AUTOSAR XML (schema 4-2-2)
package /STELLANTIS/EPT/SASWCs
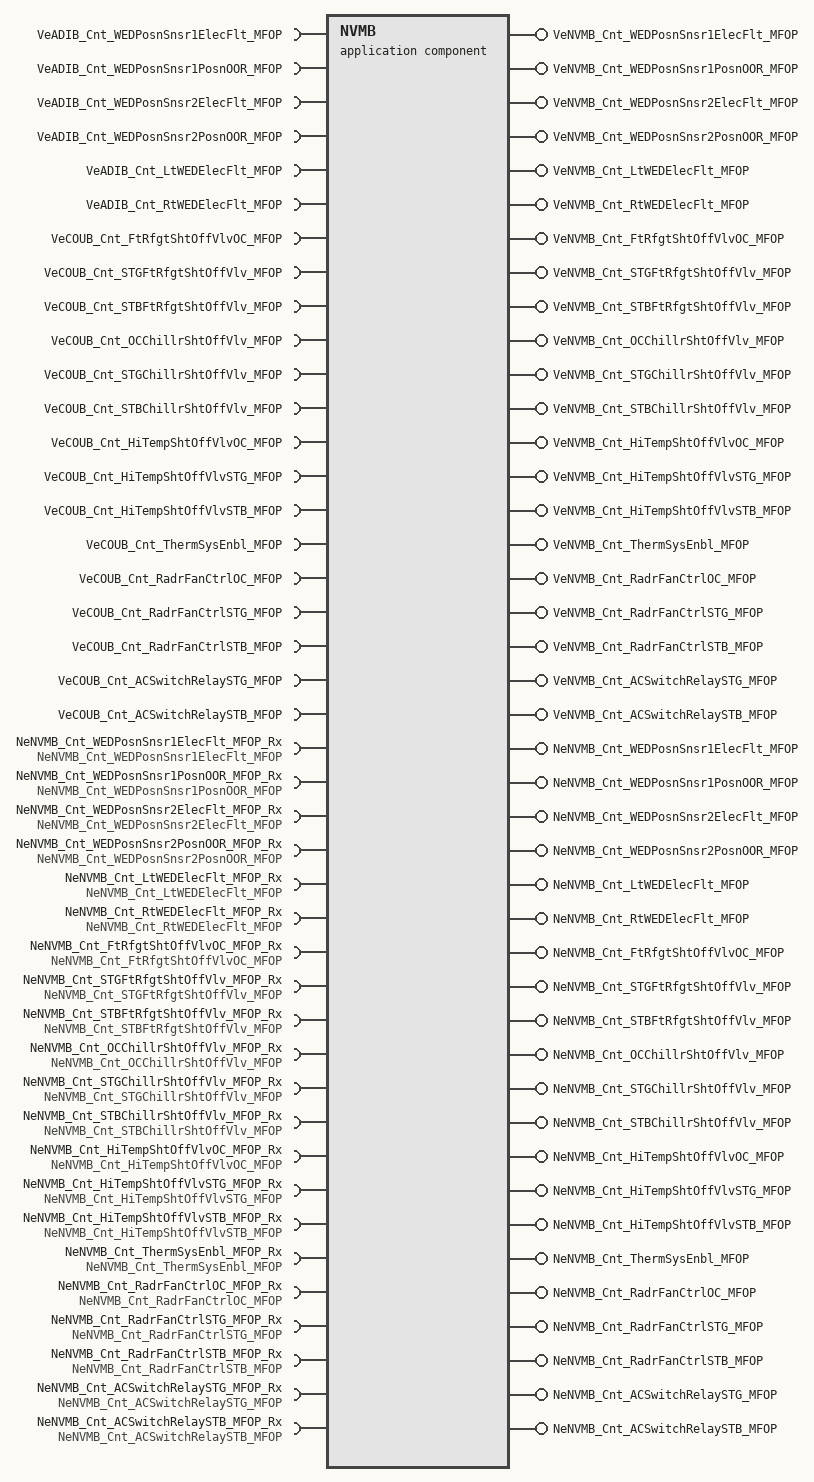
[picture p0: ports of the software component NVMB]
  application sw component type NVMB
    21 x require port, all with nonqueued-receiver-com-spec{data-element=Value, init-value=0}:
      VeADIB_Cnt_WEDPosnSnsr1ElecFlt_MFOP: variation-point={short-label=vpVeADIB_Cnt_WEDPosnSnsr1ElecFlt_MFOP, sw-syscond=1}, required-interface=VeADIB_Cnt_WEDPosnSnsr1ElecFlt_MFOP
      VeADIB_Cnt_WEDPosnSnsr1PosnOOR_MFOP: variation-point={short-label=vpVeADIB_Cnt_WEDPosnSnsr1PosnOOR_MFOP, sw-syscond=1}, required-interface=VeADIB_Cnt_WEDPosnSnsr1PosnOOR_MFOP
      VeADIB_Cnt_WEDPosnSnsr2ElecFlt_MFOP: variation-point={short-label=vpVeADIB_Cnt_WEDPosnSnsr2ElecFlt_MFOP, sw-syscond=1}, required-interface=VeADIB_Cnt_WEDPosnSnsr2ElecFlt_MFOP
      VeADIB_Cnt_WEDPosnSnsr2PosnOOR_MFOP: variation-point={short-label=vpVeADIB_Cnt_WEDPosnSnsr2PosnOOR_MFOP, sw-syscond=1}, required-interface=VeADIB_Cnt_WEDPosnSnsr2PosnOOR_MFOP
      VeADIB_Cnt_LtWEDElecFlt_MFOP: variation-point={short-label=vpVeADIB_Cnt_LtWEDElecFlt_MFOP, sw-syscond=1}, required-interface=VeADIB_Cnt_LtWEDElecFlt_MFOP
      VeADIB_Cnt_RtWEDElecFlt_MFOP: variation-point={short-label=vpVeADIB_Cnt_RtWEDElecFlt_MFOP, sw-syscond=1}, required-interface=VeADIB_Cnt_RtWEDElecFlt_MFOP
      VeCOUB_Cnt_FtRfgtShtOffVlvOC_MFOP: variation-point={short-label=vpVeCOUB_Cnt_FtRfgtShtOffVlvOC_MFOP, sw-syscond=1}, required-interface=VeCOUB_Cnt_FtRfgtShtOffVlvOC_MFOP
      VeCOUB_Cnt_STGFtRfgtShtOffVlv_MFOP: variation-point={short-label=vpVeCOUB_Cnt_STGFtRfgtShtOffVlv_MFOP, sw-syscond=1}, required-interface=VeCOUB_Cnt_STGFtRfgtShtOffVlv_MFOP
      VeCOUB_Cnt_STBFtRfgtShtOffVlv_MFOP: variation-point={short-label=vpVeCOUB_Cnt_STBFtRfgtShtOffVlv_MFOP, sw-syscond=1}, required-interface=VeCOUB_Cnt_STBFtRfgtShtOffVlv_MFOP
      VeCOUB_Cnt_OCChillrShtOffVlv_MFOP: variation-point={short-label=vpVeCOUB_Cnt_OCChillrShtOffVlv_MFOP, sw-syscond=1}, required-interface=VeCOUB_Cnt_OCChillrShtOffVlv_MFOP
      VeCOUB_Cnt_STGChillrShtOffVlv_MFOP: variation-point={short-label=vpVeCOUB_Cnt_STGChillrShtOffVlv_MFOP, sw-syscond=1}, required-interface=VeCOUB_Cnt_STGChillrShtOffVlv_MFOP
      VeCOUB_Cnt_STBChillrShtOffVlv_MFOP: variation-point={short-label=vpVeCOUB_Cnt_STBChillrShtOffVlv_MFOP, sw-syscond=1}, required-interface=VeCOUB_Cnt_STBChillrShtOffVlv_MFOP
      VeCOUB_Cnt_HiTempShtOffVlvOC_MFOP: variation-point={short-label=vpVeCOUB_Cnt_HiTempShtOffVlvOC_MFOP, sw-syscond=1}, required-interface=VeCOUB_Cnt_HiTempShtOffVlvOC_MFOP
      VeCOUB_Cnt_HiTempShtOffVlvSTG_MFOP: variation-point={short-label=vpVeCOUB_Cnt_HiTempShtOffVlvSTG_MFOP, sw-syscond=1}, required-interface=VeCOUB_Cnt_HiTempShtOffVlvSTG_MFOP
      VeCOUB_Cnt_HiTempShtOffVlvSTB_MFOP: variation-point={short-label=vpVeCOUB_Cnt_HiTempShtOffVlvSTB_MFOP, sw-syscond=1}, required-interface=VeCOUB_Cnt_HiTempShtOffVlvSTB_MFOP
      VeCOUB_Cnt_ThermSysEnbl_MFOP: variation-point={short-label=vpVeCOUB_Cnt_ThermSysEnbl_MFOP, sw-syscond=1}, required-interface=VeCOUB_Cnt_ThermSysEnbl_MFOP
      VeCOUB_Cnt_RadrFanCtrlOC_MFOP: variation-point={short-label=vpVeCOUB_Cnt_RadrFanCtrlOC_MFOP, sw-syscond=1}, required-interface=VeCOUB_Cnt_RadrFanCtrlOC_MFOP
      VeCOUB_Cnt_RadrFanCtrlSTG_MFOP: variation-point={short-label=vpVeCOUB_Cnt_RadrFanCtrlSTG_MFOP, sw-syscond=1}, required-interface=VeCOUB_Cnt_RadrFanCtrlSTG_MFOP
      VeCOUB_Cnt_RadrFanCtrlSTB_MFOP: variation-point={short-label=vpVeCOUB_Cnt_RadrFanCtrlSTB_MFOP, sw-syscond=1}, required-interface=VeCOUB_Cnt_RadrFanCtrlSTB_MFOP
      VeCOUB_Cnt_ACSwitchRelaySTG_MFOP: variation-point={short-label=vpVeCOUB_Cnt_ACSwitchRelaySTG_MFOP, sw-syscond=1}, required-interface=VeCOUB_Cnt_ACSwitchRelaySTG_MFOP
      VeCOUB_Cnt_ACSwitchRelaySTB_MFOP: variation-point={short-label=vpVeCOUB_Cnt_ACSwitchRelaySTB_MFOP, sw-syscond=1}, required-interface=VeCOUB_Cnt_ACSwitchRelaySTB_MFOP
    21 x provide port, all with nonqueued-sender-com-spec{data-element=Value, init-value=0}:
      VeNVMB_Cnt_WEDPosnSnsr1ElecFlt_MFOP: variation-point={short-label=vpVeNVMB_Cnt_WEDPosnSnsr1ElecFlt_MFOP, sw-syscond=1}, provided-interface=VeNVMB_Cnt_WEDPosnSnsr1ElecFlt_MFOP
      VeNVMB_Cnt_WEDPosnSnsr1PosnOOR_MFOP: variation-point={short-label=vpVeNVMB_Cnt_WEDPosnSnsr1PosnOOR_MFOP, sw-syscond=1}, provided-interface=VeNVMB_Cnt_WEDPosnSnsr1PosnOOR_MFOP
      VeNVMB_Cnt_WEDPosnSnsr2ElecFlt_MFOP: variation-point={short-label=vpVeNVMB_Cnt_WEDPosnSnsr2ElecFlt_MFOP, sw-syscond=1}, provided-interface=VeNVMB_Cnt_WEDPosnSnsr2ElecFlt_MFOP
      VeNVMB_Cnt_WEDPosnSnsr2PosnOOR_MFOP: variation-point={short-label=vpVeNVMB_Cnt_WEDPosnSnsr2PosnOOR_MFOP, sw-syscond=1}, provided-interface=VeNVMB_Cnt_WEDPosnSnsr2PosnOOR_MFOP
      VeNVMB_Cnt_LtWEDElecFlt_MFOP: variation-point={short-label=vpVeNVMB_Cnt_LtWEDElecFlt_MFOP, sw-syscond=1}, provided-interface=VeNVMB_Cnt_LtWEDElecFlt_MFOP
      VeNVMB_Cnt_RtWEDElecFlt_MFOP: variation-point={short-label=vpVeNVMB_Cnt_RtWEDElecFlt_MFOP, sw-syscond=1}, provided-interface=VeNVMB_Cnt_RtWEDElecFlt_MFOP
      VeNVMB_Cnt_FtRfgtShtOffVlvOC_MFOP: variation-point={short-label=vpVeNVMB_Cnt_FtRfgtShtOffVlvOC_MFOP, sw-syscond=1}, provided-interface=VeNVMB_Cnt_FtRfgtShtOffVlvOC_MFOP
      VeNVMB_Cnt_STGFtRfgtShtOffVlv_MFOP: variation-point={short-label=vpVeNVMB_Cnt_STGFtRfgtShtOffVlv_MFOP, sw-syscond=1}, provided-interface=VeNVMB_Cnt_STGFtRfgtShtOffVlv_MFOP
      VeNVMB_Cnt_STBFtRfgtShtOffVlv_MFOP: variation-point={short-label=vpVeNVMB_Cnt_STBFtRfgtShtOffVlv_MFOP, sw-syscond=1}, provided-interface=VeNVMB_Cnt_STBFtRfgtShtOffVlv_MFOP
      VeNVMB_Cnt_OCChillrShtOffVlv_MFOP: variation-point={short-label=vpVeNVMB_Cnt_OCChillrShtOffVlv_MFOP, sw-syscond=1}, provided-interface=VeNVMB_Cnt_OCChillrShtOffVlv_MFOP
      VeNVMB_Cnt_STGChillrShtOffVlv_MFOP: variation-point={short-label=vpVeNVMB_Cnt_STGChillrShtOffVlv_MFOP, sw-syscond=1}, provided-interface=VeNVMB_Cnt_STGChillrShtOffVlv_MFOP
      VeNVMB_Cnt_STBChillrShtOffVlv_MFOP: variation-point={short-label=vpVeNVMB_Cnt_STBChillrShtOffVlv_MFOP, sw-syscond=1}, provided-interface=VeNVMB_Cnt_STBChillrShtOffVlv_MFOP
      VeNVMB_Cnt_HiTempShtOffVlvOC_MFOP: variation-point={short-label=vpVeNVMB_Cnt_HiTempShtOffVlvOC_MFOP, sw-syscond=1}, provided-interface=VeNVMB_Cnt_HiTempShtOffVlvOC_MFOP
      VeNVMB_Cnt_HiTempShtOffVlvSTG_MFOP: variation-point={short-label=vpVeNVMB_Cnt_HiTempShtOffVlvSTG_MFOP, sw-syscond=1}, provided-interface=VeNVMB_Cnt_HiTempShtOffVlvSTG_MFOP
      VeNVMB_Cnt_HiTempShtOffVlvSTB_MFOP: variation-point={short-label=vpVeNVMB_Cnt_HiTempShtOffVlvSTB_MFOP, sw-syscond=1}, provided-interface=VeNVMB_Cnt_HiTempShtOffVlvSTB_MFOP
      VeNVMB_Cnt_ThermSysEnbl_MFOP: variation-point={short-label=vpVeNVMB_Cnt_ThermSysEnbl_MFOP, sw-syscond=1}, provided-interface=VeNVMB_Cnt_ThermSysEnbl_MFOP
      VeNVMB_Cnt_RadrFanCtrlOC_MFOP: variation-point={short-label=vpVeNVMB_Cnt_RadrFanCtrlOC_MFOP, sw-syscond=1}, provided-interface=VeNVMB_Cnt_RadrFanCtrlOC_MFOP
      VeNVMB_Cnt_RadrFanCtrlSTG_MFOP: variation-point={short-label=vpVeNVMB_Cnt_RadrFanCtrlSTG_MFOP, sw-syscond=1}, provided-interface=VeNVMB_Cnt_RadrFanCtrlSTG_MFOP
      VeNVMB_Cnt_RadrFanCtrlSTB_MFOP: variation-point={short-label=vpVeNVMB_Cnt_RadrFanCtrlSTB_MFOP, sw-syscond=1}, provided-interface=VeNVMB_Cnt_RadrFanCtrlSTB_MFOP
      VeNVMB_Cnt_ACSwitchRelaySTG_MFOP: variation-point={short-label=vpVeNVMB_Cnt_ACSwitchRelaySTG_MFOP, sw-syscond=1}, provided-interface=VeNVMB_Cnt_ACSwitchRelaySTG_MFOP
      VeNVMB_Cnt_ACSwitchRelaySTB_MFOP: variation-point={short-label=vpVeNVMB_Cnt_ACSwitchRelaySTB_MFOP, sw-syscond=1}, provided-interface=VeNVMB_Cnt_ACSwitchRelaySTB_MFOP
    21 x require port:
      NeNVMB_Cnt_WEDPosnSnsr1ElecFlt_MFOP_Rx: variation-point={short-label=vpNeNVMB_Cnt_WEDPosnSnsr1ElecFlt_MFOP_Rx, sw-syscond=1}, nv-require-com-spec{init-value=0, variable=NeNVMB_Cnt_WEDPosnSnsr1ElecFlt_MFOP}, required-interface=NeNVMB_Cnt_WEDPosnSnsr1ElecFlt_MFOP
      NeNVMB_Cnt_WEDPosnSnsr1PosnOOR_MFOP_Rx: variation-point={short-label=vpNeNVMB_Cnt_WEDPosnSnsr1PosnOOR_MFOP_Rx, sw-syscond=1}, nv-require-com-spec{init-value=0, variable=NeNVMB_Cnt_WEDPosnSnsr1PosnOOR_MFOP}, required-interface=NeNVMB_Cnt_WEDPosnSnsr1PosnOOR_MFOP
      NeNVMB_Cnt_WEDPosnSnsr2ElecFlt_MFOP_Rx: variation-point={short-label=vpNeNVMB_Cnt_WEDPosnSnsr2ElecFlt_MFOP_Rx, sw-syscond=1}, nv-require-com-spec{init-value=0, variable=NeNVMB_Cnt_WEDPosnSnsr2ElecFlt_MFOP}, required-interface=NeNVMB_Cnt_WEDPosnSnsr2ElecFlt_MFOP
      NeNVMB_Cnt_WEDPosnSnsr2PosnOOR_MFOP_Rx: variation-point={short-label=vpNeNVMB_Cnt_WEDPosnSnsr2PosnOOR_MFOP_Rx, sw-syscond=1}, nv-require-com-spec{init-value=0, variable=NeNVMB_Cnt_WEDPosnSnsr2PosnOOR_MFOP}, required-interface=NeNVMB_Cnt_WEDPosnSnsr2PosnOOR_MFOP
      NeNVMB_Cnt_LtWEDElecFlt_MFOP_Rx: variation-point={short-label=vpNeNVMB_Cnt_LtWEDElecFlt_MFOP_Rx, sw-syscond=1}, nv-require-com-spec{init-value=0, variable=NeNVMB_Cnt_LtWEDElecFlt_MFOP}, required-interface=NeNVMB_Cnt_LtWEDElecFlt_MFOP
      NeNVMB_Cnt_RtWEDElecFlt_MFOP_Rx: variation-point={short-label=vpNeNVMB_Cnt_RtWEDElecFlt_MFOP_Rx, sw-syscond=1}, nv-require-com-spec{init-value=0, variable=NeNVMB_Cnt_RtWEDElecFlt_MFOP}, required-interface=NeNVMB_Cnt_RtWEDElecFlt_MFOP
      NeNVMB_Cnt_FtRfgtShtOffVlvOC_MFOP_Rx: variation-point={short-label=vpNeNVMB_Cnt_FtRfgtShtOffVlvOC_MFOP_Rx, sw-syscond=1}, nv-require-com-spec{init-value=0, variable=NeNVMB_Cnt_FtRfgtShtOffVlvOC_MFOP}, required-interface=NeNVMB_Cnt_FtRfgtShtOffVlvOC_MFOP
      NeNVMB_Cnt_STGFtRfgtShtOffVlv_MFOP_Rx: variation-point={short-label=vpNeNVMB_Cnt_STGFtRfgtShtOffVlv_MFOP_Rx, sw-syscond=1}, nv-require-com-spec{init-value=0, variable=NeNVMB_Cnt_STGFtRfgtShtOffVlv_MFOP}, required-interface=NeNVMB_Cnt_STGFtRfgtShtOffVlv_MFOP
      NeNVMB_Cnt_STBFtRfgtShtOffVlv_MFOP_Rx: variation-point={short-label=vpNeNVMB_Cnt_STBFtRfgtShtOffVlv_MFOP_Rx, sw-syscond=1}, nv-require-com-spec{init-value=0, variable=NeNVMB_Cnt_STBFtRfgtShtOffVlv_MFOP}, required-interface=NeNVMB_Cnt_STBFtRfgtShtOffVlv_MFOP
      NeNVMB_Cnt_OCChillrShtOffVlv_MFOP_Rx: variation-point={short-label=vpNeNVMB_Cnt_OCChillrShtOffVlv_MFOP_Rx, sw-syscond=1}, nv-require-com-spec{init-value=0, variable=NeNVMB_Cnt_OCChillrShtOffVlv_MFOP}, required-interface=NeNVMB_Cnt_OCChillrShtOffVlv_MFOP
      NeNVMB_Cnt_STGChillrShtOffVlv_MFOP_Rx: variation-point={short-label=vpNeNVMB_Cnt_STGChillrShtOffVlv_MFOP_Rx, sw-syscond=1}, nv-require-com-spec{init-value=0, variable=NeNVMB_Cnt_STGChillrShtOffVlv_MFOP}, required-interface=NeNVMB_Cnt_STGChillrShtOffVlv_MFOP
      NeNVMB_Cnt_STBChillrShtOffVlv_MFOP_Rx: variation-point={short-label=vpNeNVMB_Cnt_STBChillrShtOffVlv_MFOP_Rx, sw-syscond=1}, nv-require-com-spec{init-value=0, variable=NeNVMB_Cnt_STBChillrShtOffVlv_MFOP}, required-interface=NeNVMB_Cnt_STBChillrShtOffVlv_MFOP
      NeNVMB_Cnt_HiTempShtOffVlvOC_MFOP_Rx: variation-point={short-label=vpNeNVMB_Cnt_HiTempShtOffVlvOC_MFOP_Rx, sw-syscond=1}, nv-require-com-spec{init-value=0, variable=NeNVMB_Cnt_HiTempShtOffVlvOC_MFOP}, required-interface=NeNVMB_Cnt_HiTempShtOffVlvOC_MFOP
      NeNVMB_Cnt_HiTempShtOffVlvSTG_MFOP_Rx: variation-point={short-label=vpNeNVMB_Cnt_HiTempShtOffVlvSTG_MFOP_Rx, sw-syscond=1}, nv-require-com-spec{init-value=0, variable=NeNVMB_Cnt_HiTempShtOffVlvSTG_MFOP}, required-interface=NeNVMB_Cnt_HiTempShtOffVlvSTG_MFOP
      NeNVMB_Cnt_HiTempShtOffVlvSTB_MFOP_Rx: variation-point={short-label=vpNeNVMB_Cnt_HiTempShtOffVlvSTB_MFOP_Rx, sw-syscond=1}, nv-require-com-spec{init-value=0, variable=NeNVMB_Cnt_HiTempShtOffVlvSTB_MFOP}, required-interface=NeNVMB_Cnt_HiTempShtOffVlvSTB_MFOP
      NeNVMB_Cnt_ThermSysEnbl_MFOP_Rx: variation-point={short-label=vpNeNVMB_Cnt_ThermSysEnbl_MFOP_Rx, sw-syscond=1}, nv-require-com-spec{init-value=0, variable=NeNVMB_Cnt_ThermSysEnbl_MFOP}, required-interface=NeNVMB_Cnt_ThermSysEnbl_MFOP
      NeNVMB_Cnt_RadrFanCtrlOC_MFOP_Rx: variation-point={short-label=vpNeNVMB_Cnt_RadrFanCtrlOC_MFOP_Rx, sw-syscond=1}, nv-require-com-spec{init-value=0, variable=NeNVMB_Cnt_RadrFanCtrlOC_MFOP}, required-interface=NeNVMB_Cnt_RadrFanCtrlOC_MFOP
      NeNVMB_Cnt_RadrFanCtrlSTG_MFOP_Rx: variation-point={short-label=vpNeNVMB_Cnt_RadrFanCtrlSTG_MFOP_Rx, sw-syscond=1}, nv-require-com-spec{init-value=0, variable=NeNVMB_Cnt_RadrFanCtrlSTG_MFOP}, required-interface=NeNVMB_Cnt_RadrFanCtrlSTG_MFOP
      NeNVMB_Cnt_RadrFanCtrlSTB_MFOP_Rx: variation-point={short-label=vpNeNVMB_Cnt_RadrFanCtrlSTB_MFOP_Rx, sw-syscond=1}, nv-require-com-spec{init-value=0, variable=NeNVMB_Cnt_RadrFanCtrlSTB_MFOP}, required-interface=NeNVMB_Cnt_RadrFanCtrlSTB_MFOP
      NeNVMB_Cnt_ACSwitchRelaySTG_MFOP_Rx: variation-point={short-label=vpNeNVMB_Cnt_ACSwitchRelaySTG_MFOP_Rx, sw-syscond=1}, nv-require-com-spec{init-value=0, variable=NeNVMB_Cnt_ACSwitchRelaySTG_MFOP}, required-interface=NeNVMB_Cnt_ACSwitchRelaySTG_MFOP
      NeNVMB_Cnt_ACSwitchRelaySTB_MFOP_Rx: variation-point={short-label=vpNeNVMB_Cnt_ACSwitchRelaySTB_MFOP_Rx, sw-syscond=1}, nv-require-com-spec{init-value=0, variable=NeNVMB_Cnt_ACSwitchRelaySTB_MFOP}, required-interface=NeNVMB_Cnt_ACSwitchRelaySTB_MFOP
    21 x provide port:
      NeNVMB_Cnt_WEDPosnSnsr1ElecFlt_MFOP: variation-point={short-label=vpNeNVMB_Cnt_WEDPosnSnsr1ElecFlt_MFOP, sw-syscond=1}, nv-provide-com-spec{ram-block-init-value=0, variable=NeNVMB_Cnt_WEDPosnSnsr1ElecFlt_MFOP}, provided-interface=NeNVMB_Cnt_WEDPosnSnsr1ElecFlt_MFOP
      NeNVMB_Cnt_WEDPosnSnsr1PosnOOR_MFOP: variation-point={short-label=vpNeNVMB_Cnt_WEDPosnSnsr1PosnOOR_MFOP, sw-syscond=1}, nv-provide-com-spec{ram-block-init-value=0, variable=NeNVMB_Cnt_WEDPosnSnsr1PosnOOR_MFOP}, provided-interface=NeNVMB_Cnt_WEDPosnSnsr1PosnOOR_MFOP
      NeNVMB_Cnt_WEDPosnSnsr2ElecFlt_MFOP: variation-point={short-label=vpNeNVMB_Cnt_WEDPosnSnsr2ElecFlt_MFOP, sw-syscond=1}, nv-provide-com-spec{ram-block-init-value=0, variable=NeNVMB_Cnt_WEDPosnSnsr2ElecFlt_MFOP}, provided-interface=NeNVMB_Cnt_WEDPosnSnsr2ElecFlt_MFOP
      NeNVMB_Cnt_WEDPosnSnsr2PosnOOR_MFOP: variation-point={short-label=vpNeNVMB_Cnt_WEDPosnSnsr2PosnOOR_MFOP, sw-syscond=1}, nv-provide-com-spec{ram-block-init-value=0, variable=NeNVMB_Cnt_WEDPosnSnsr2PosnOOR_MFOP}, provided-interface=NeNVMB_Cnt_WEDPosnSnsr2PosnOOR_MFOP
      NeNVMB_Cnt_LtWEDElecFlt_MFOP: variation-point={short-label=vpNeNVMB_Cnt_LtWEDElecFlt_MFOP, sw-syscond=1}, nv-provide-com-spec{ram-block-init-value=0, variable=NeNVMB_Cnt_LtWEDElecFlt_MFOP}, provided-interface=NeNVMB_Cnt_LtWEDElecFlt_MFOP
      NeNVMB_Cnt_RtWEDElecFlt_MFOP: variation-point={short-label=vpNeNVMB_Cnt_RtWEDElecFlt_MFOP, sw-syscond=1}, nv-provide-com-spec{ram-block-init-value=0, variable=NeNVMB_Cnt_RtWEDElecFlt_MFOP}, provided-interface=NeNVMB_Cnt_RtWEDElecFlt_MFOP
      NeNVMB_Cnt_FtRfgtShtOffVlvOC_MFOP: variation-point={short-label=vpNeNVMB_Cnt_FtRfgtShtOffVlvOC_MFOP, sw-syscond=1}, nv-provide-com-spec{ram-block-init-value=0, variable=NeNVMB_Cnt_FtRfgtShtOffVlvOC_MFOP}, provided-interface=NeNVMB_Cnt_FtRfgtShtOffVlvOC_MFOP
      NeNVMB_Cnt_STGFtRfgtShtOffVlv_MFOP: variation-point={short-label=vpNeNVMB_Cnt_STGFtRfgtShtOffVlv_MFOP, sw-syscond=1}, nv-provide-com-spec{ram-block-init-value=0, variable=NeNVMB_Cnt_STGFtRfgtShtOffVlv_MFOP}, provided-interface=NeNVMB_Cnt_STGFtRfgtShtOffVlv_MFOP
      NeNVMB_Cnt_STBFtRfgtShtOffVlv_MFOP: variation-point={short-label=vpNeNVMB_Cnt_STBFtRfgtShtOffVlv_MFOP, sw-syscond=1}, nv-provide-com-spec{ram-block-init-value=0, variable=NeNVMB_Cnt_STBFtRfgtShtOffVlv_MFOP}, provided-interface=NeNVMB_Cnt_STBFtRfgtShtOffVlv_MFOP
      NeNVMB_Cnt_OCChillrShtOffVlv_MFOP: variation-point={short-label=vpNeNVMB_Cnt_OCChillrShtOffVlv_MFOP, sw-syscond=1}, nv-provide-com-spec{ram-block-init-value=0, variable=NeNVMB_Cnt_OCChillrShtOffVlv_MFOP}, provided-interface=NeNVMB_Cnt_OCChillrShtOffVlv_MFOP
      NeNVMB_Cnt_STGChillrShtOffVlv_MFOP: variation-point={short-label=vpNeNVMB_Cnt_STGChillrShtOffVlv_MFOP, sw-syscond=1}, nv-provide-com-spec{ram-block-init-value=0, variable=NeNVMB_Cnt_STGChillrShtOffVlv_MFOP}, provided-interface=NeNVMB_Cnt_STGChillrShtOffVlv_MFOP
      NeNVMB_Cnt_STBChillrShtOffVlv_MFOP: variation-point={short-label=vpNeNVMB_Cnt_STBChillrShtOffVlv_MFOP, sw-syscond=1}, nv-provide-com-spec{ram-block-init-value=0, variable=NeNVMB_Cnt_STBChillrShtOffVlv_MFOP}, provided-interface=NeNVMB_Cnt_STBChillrShtOffVlv_MFOP
      NeNVMB_Cnt_HiTempShtOffVlvOC_MFOP: variation-point={short-label=vpNeNVMB_Cnt_HiTempShtOffVlvOC_MFOP, sw-syscond=1}, nv-provide-com-spec{ram-block-init-value=0, variable=NeNVMB_Cnt_HiTempShtOffVlvOC_MFOP}, provided-interface=NeNVMB_Cnt_HiTempShtOffVlvOC_MFOP
      NeNVMB_Cnt_HiTempShtOffVlvSTG_MFOP: variation-point={short-label=vpNeNVMB_Cnt_HiTempShtOffVlvSTG_MFOP, sw-syscond=1}, nv-provide-com-spec{ram-block-init-value=0, variable=NeNVMB_Cnt_HiTempShtOffVlvSTG_MFOP}, provided-interface=NeNVMB_Cnt_HiTempShtOffVlvSTG_MFOP
      NeNVMB_Cnt_HiTempShtOffVlvSTB_MFOP: variation-point={short-label=vpNeNVMB_Cnt_HiTempShtOffVlvSTB_MFOP, sw-syscond=1}, nv-provide-com-spec{ram-block-init-value=0, variable=NeNVMB_Cnt_HiTempShtOffVlvSTB_MFOP}, provided-interface=NeNVMB_Cnt_HiTempShtOffVlvSTB_MFOP
      NeNVMB_Cnt_ThermSysEnbl_MFOP: variation-point={short-label=vpNeNVMB_Cnt_ThermSysEnbl_MFOP, sw-syscond=1}, nv-provide-com-spec{ram-block-init-value=0, variable=NeNVMB_Cnt_ThermSysEnbl_MFOP}, provided-interface=NeNVMB_Cnt_ThermSysEnbl_MFOP
      NeNVMB_Cnt_RadrFanCtrlOC_MFOP: variation-point={short-label=vpNeNVMB_Cnt_RadrFanCtrlOC_MFOP, sw-syscond=1}, nv-provide-com-spec{ram-block-init-value=0, variable=NeNVMB_Cnt_RadrFanCtrlOC_MFOP}, provided-interface=NeNVMB_Cnt_RadrFanCtrlOC_MFOP
      NeNVMB_Cnt_RadrFanCtrlSTG_MFOP: variation-point={short-label=vpNeNVMB_Cnt_RadrFanCtrlSTG_MFOP, sw-syscond=1}, nv-provide-com-spec{ram-block-init-value=0, variable=NeNVMB_Cnt_RadrFanCtrlSTG_MFOP}, provided-interface=NeNVMB_Cnt_RadrFanCtrlSTG_MFOP
      NeNVMB_Cnt_RadrFanCtrlSTB_MFOP: variation-point={short-label=vpNeNVMB_Cnt_RadrFanCtrlSTB_MFOP, sw-syscond=1}, nv-provide-com-spec{ram-block-init-value=0, variable=NeNVMB_Cnt_RadrFanCtrlSTB_MFOP}, provided-interface=NeNVMB_Cnt_RadrFanCtrlSTB_MFOP
      NeNVMB_Cnt_ACSwitchRelaySTG_MFOP: variation-point={short-label=vpNeNVMB_Cnt_ACSwitchRelaySTG_MFOP, sw-syscond=1}, nv-provide-com-spec{ram-block-init-value=0, variable=NeNVMB_Cnt_ACSwitchRelaySTG_MFOP}, provided-interface=NeNVMB_Cnt_ACSwitchRelaySTG_MFOP
      NeNVMB_Cnt_ACSwitchRelaySTB_MFOP: variation-point={short-label=vpNeNVMB_Cnt_ACSwitchRelaySTB_MFOP, sw-syscond=1}, nv-provide-com-spec{ram-block-init-value=0, variable=NeNVMB_Cnt_ACSwitchRelaySTB_MFOP}, provided-interface=NeNVMB_Cnt_ACSwitchRelaySTB_MFOP
    behavior IB_NVMB: data-type-mapping=msADTtoIDTMapping, handle-termination-and-restart=NO-SUPPORT
      6 x timing event:
        Event_MedTED1: start-on-event=NVMB_MedTED1, period=0.02
        Event_MedTEB1: start-on-event=NVMB_MedTEB1, period=0.01
        Event_MedTEB2: start-on-event=NVMB_MedTEB2, period=0.01
        Event_MedTED2: start-on-event=NVMB_MedTED2, period=0.02
        Event_MedTEH1: start-on-event=NVMB_MedTEH1, period=0.1
        Event_MedTEH2: start-on-event=NVMB_MedTEH2, period=0.1
      init event Event_NVMB_ac_Init: start-on-event=NVMB_ac_Init
      init event Event_PwrOff: start-on-event=NVMB_PwrOff
      8 x runnable:
        NVMB_ac_Init
          data-receive-point-by-arguments:
            21 x access:
              IN_NeNVMB_Cnt_ACSwitchRelaySTB_MFOP_Rx_NeNVMB_Cnt_ACSwitchRelaySTB_MFOP: accessed-variable=NeNVMB_Cnt_ACSwitchRelaySTB_MFOP_Rx.NeNVMB_Cnt_ACSwitchRelaySTB_MFOP, variation-point={short-label=vpIN_NeNVMB_Cnt_ACSwitchRelaySTB_MFOP_Rx_NeNVMB_Cnt_ACSwitchRelaySTB_MFOP, sw-syscond=1}
              IN_NeNVMB_Cnt_ACSwitchRelaySTG_MFOP_Rx_NeNVMB_Cnt_ACSwitchRelaySTG_MFOP: accessed-variable=NeNVMB_Cnt_ACSwitchRelaySTG_MFOP_Rx.NeNVMB_Cnt_ACSwitchRelaySTG_MFOP, variation-point={short-label=vpIN_NeNVMB_Cnt_ACSwitchRelaySTG_MFOP_Rx_NeNVMB_Cnt_ACSwitchRelaySTG_MFOP, sw-syscond=1}
              IN_NeNVMB_Cnt_FtRfgtShtOffVlvOC_MFOP_Rx_NeNVMB_Cnt_FtRfgtShtOffVlvOC_MFOP: accessed-variable=NeNVMB_Cnt_FtRfgtShtOffVlvOC_MFOP_Rx.NeNVMB_Cnt_FtRfgtShtOffVlvOC_MFOP, variation-point={short-label=vpIN_NeNVMB_Cnt_FtRfgtShtOffVlvOC_MFOP_Rx_NeNVMB_Cnt_FtRfgtShtOffVlvOC_MFOP, sw-syscond=1}
              IN_NeNVMB_Cnt_HiTempShtOffVlvOC_MFOP_Rx_NeNVMB_Cnt_HiTempShtOffVlvOC_MFOP: accessed-variable=NeNVMB_Cnt_HiTempShtOffVlvOC_MFOP_Rx.NeNVMB_Cnt_HiTempShtOffVlvOC_MFOP, variation-point={short-label=vpIN_NeNVMB_Cnt_HiTempShtOffVlvOC_MFOP_Rx_NeNVMB_Cnt_HiTempShtOffVlvOC_MFOP, sw-syscond=1}
              IN_NeNVMB_Cnt_HiTempShtOffVlvSTB_MFOP_Rx_NeNVMB_Cnt_HiTempShtOffVlvSTB_MFOP: accessed-variable=NeNVMB_Cnt_HiTempShtOffVlvSTB_MFOP_Rx.NeNVMB_Cnt_HiTempShtOffVlvSTB_MFOP, variation-point={short-label=vpIN_NeNVMB_Cnt_HiTempShtOffVlvSTB_MFOP_Rx_NeNVMB_Cnt_HiTempShtOffVlvSTB_MFOP, sw-syscond=1}
              IN_NeNVMB_Cnt_HiTempShtOffVlvSTG_MFOP_Rx_NeNVMB_Cnt_HiTempShtOffVlvSTG_MFOP: accessed-variable=NeNVMB_Cnt_HiTempShtOffVlvSTG_MFOP_Rx.NeNVMB_Cnt_HiTempShtOffVlvSTG_MFOP, variation-point={short-label=vpIN_NeNVMB_Cnt_HiTempShtOffVlvSTG_MFOP_Rx_NeNVMB_Cnt_HiTempShtOffVlvSTG_MFOP, sw-syscond=1}
              IN_NeNVMB_Cnt_LtWEDElecFlt_MFOP_Rx_NeNVMB_Cnt_LtWEDElecFlt_MFOP: accessed-variable=NeNVMB_Cnt_LtWEDElecFlt_MFOP_Rx.NeNVMB_Cnt_LtWEDElecFlt_MFOP, variation-point={short-label=vpIN_NeNVMB_Cnt_LtWEDElecFlt_MFOP_Rx_NeNVMB_Cnt_LtWEDElecFlt_MFOP, sw-syscond=1}
              IN_NeNVMB_Cnt_OCChillrShtOffVlv_MFOP_Rx_NeNVMB_Cnt_OCChillrShtOffVlv_MFOP: accessed-variable=NeNVMB_Cnt_OCChillrShtOffVlv_MFOP_Rx.NeNVMB_Cnt_OCChillrShtOffVlv_MFOP, variation-point={short-label=vpIN_NeNVMB_Cnt_OCChillrShtOffVlv_MFOP_Rx_NeNVMB_Cnt_OCChillrShtOffVlv_MFOP, sw-syscond=1}
              IN_NeNVMB_Cnt_RadrFanCtrlOC_MFOP_Rx_NeNVMB_Cnt_RadrFanCtrlOC_MFOP: accessed-variable=NeNVMB_Cnt_RadrFanCtrlOC_MFOP_Rx.NeNVMB_Cnt_RadrFanCtrlOC_MFOP, variation-point={short-label=vpIN_NeNVMB_Cnt_RadrFanCtrlOC_MFOP_Rx_NeNVMB_Cnt_RadrFanCtrlOC_MFOP, sw-syscond=1}
              IN_NeNVMB_Cnt_RadrFanCtrlSTB_MFOP_Rx_NeNVMB_Cnt_RadrFanCtrlSTB_MFOP: accessed-variable=NeNVMB_Cnt_RadrFanCtrlSTB_MFOP_Rx.NeNVMB_Cnt_RadrFanCtrlSTB_MFOP, variation-point={short-label=vpIN_NeNVMB_Cnt_RadrFanCtrlSTB_MFOP_Rx_NeNVMB_Cnt_RadrFanCtrlSTB_MFOP, sw-syscond=1}
              IN_NeNVMB_Cnt_RadrFanCtrlSTG_MFOP_Rx_NeNVMB_Cnt_RadrFanCtrlSTG_MFOP: accessed-variable=NeNVMB_Cnt_RadrFanCtrlSTG_MFOP_Rx.NeNVMB_Cnt_RadrFanCtrlSTG_MFOP, variation-point={short-label=vpIN_NeNVMB_Cnt_RadrFanCtrlSTG_MFOP_Rx_NeNVMB_Cnt_RadrFanCtrlSTG_MFOP, sw-syscond=1}
              IN_NeNVMB_Cnt_RtWEDElecFlt_MFOP_Rx_NeNVMB_Cnt_RtWEDElecFlt_MFOP: accessed-variable=NeNVMB_Cnt_RtWEDElecFlt_MFOP_Rx.NeNVMB_Cnt_RtWEDElecFlt_MFOP, variation-point={short-label=vpIN_NeNVMB_Cnt_RtWEDElecFlt_MFOP_Rx_NeNVMB_Cnt_RtWEDElecFlt_MFOP, sw-syscond=1}
              IN_NeNVMB_Cnt_STBChillrShtOffVlv_MFOP_Rx_NeNVMB_Cnt_STBChillrShtOffVlv_MFOP: accessed-variable=NeNVMB_Cnt_STBChillrShtOffVlv_MFOP_Rx.NeNVMB_Cnt_STBChillrShtOffVlv_MFOP, variation-point={short-label=vpIN_NeNVMB_Cnt_STBChillrShtOffVlv_MFOP_Rx_NeNVMB_Cnt_STBChillrShtOffVlv_MFOP, sw-syscond=1}
              IN_NeNVMB_Cnt_STBFtRfgtShtOffVlv_MFOP_Rx_NeNVMB_Cnt_STBFtRfgtShtOffVlv_MFOP: accessed-variable=NeNVMB_Cnt_STBFtRfgtShtOffVlv_MFOP_Rx.NeNVMB_Cnt_STBFtRfgtShtOffVlv_MFOP, variation-point={short-label=vpIN_NeNVMB_Cnt_STBFtRfgtShtOffVlv_MFOP_Rx_NeNVMB_Cnt_STBFtRfgtShtOffVlv_MFOP, sw-syscond=1}
              IN_NeNVMB_Cnt_STGChillrShtOffVlv_MFOP_Rx_NeNVMB_Cnt_STGChillrShtOffVlv_MFOP: accessed-variable=NeNVMB_Cnt_STGChillrShtOffVlv_MFOP_Rx.NeNVMB_Cnt_STGChillrShtOffVlv_MFOP, variation-point={short-label=vpIN_NeNVMB_Cnt_STGChillrShtOffVlv_MFOP_Rx_NeNVMB_Cnt_STGChillrShtOffVlv_MFOP, sw-syscond=1}
              IN_NeNVMB_Cnt_STGFtRfgtShtOffVlv_MFOP_Rx_NeNVMB_Cnt_STGFtRfgtShtOffVlv_MFOP: accessed-variable=NeNVMB_Cnt_STGFtRfgtShtOffVlv_MFOP_Rx.NeNVMB_Cnt_STGFtRfgtShtOffVlv_MFOP, variation-point={short-label=vpIN_NeNVMB_Cnt_STGFtRfgtShtOffVlv_MFOP_Rx_NeNVMB_Cnt_STGFtRfgtShtOffVlv_MFOP, sw-syscond=1}
              IN_NeNVMB_Cnt_ThermSysEnbl_MFOP_Rx_NeNVMB_Cnt_ThermSysEnbl_MFOP: accessed-variable=NeNVMB_Cnt_ThermSysEnbl_MFOP_Rx.NeNVMB_Cnt_ThermSysEnbl_MFOP, variation-point={short-label=vpIN_NeNVMB_Cnt_ThermSysEnbl_MFOP_Rx_NeNVMB_Cnt_ThermSysEnbl_MFOP, sw-syscond=1}
              IN_NeNVMB_Cnt_WEDPosnSnsr1ElecFlt_MFOP_Rx_NeNVMB_Cnt_WEDPosnSnsr1ElecFlt_MFOP: accessed-variable=NeNVMB_Cnt_WEDPosnSnsr1ElecFlt_MFOP_Rx.NeNVMB_Cnt_WEDPosnSnsr1ElecFlt_MFOP, variation-point={short-label=vpIN_NeNVMB_Cnt_WEDPosnSnsr1ElecFlt_MFOP_Rx_NeNVMB_Cnt_WEDPosnSnsr1ElecFlt_MFOP, sw-syscond=1}
              IN_NeNVMB_Cnt_WEDPosnSnsr1PosnOOR_MFOP_Rx_NeNVMB_Cnt_WEDPosnSnsr1PosnOOR_MFOP: accessed-variable=NeNVMB_Cnt_WEDPosnSnsr1PosnOOR_MFOP_Rx.NeNVMB_Cnt_WEDPosnSnsr1PosnOOR_MFOP, variation-point={short-label=vpIN_NeNVMB_Cnt_WEDPosnSnsr1PosnOOR_MFOP_Rx_NeNVMB_Cnt_WEDPosnSnsr1PosnOOR_MFOP, sw-syscond=1}
              IN_NeNVMB_Cnt_WEDPosnSnsr2ElecFlt_MFOP_Rx_NeNVMB_Cnt_WEDPosnSnsr2ElecFlt_MFOP: accessed-variable=NeNVMB_Cnt_WEDPosnSnsr2ElecFlt_MFOP_Rx.NeNVMB_Cnt_WEDPosnSnsr2ElecFlt_MFOP, variation-point={short-label=vpIN_NeNVMB_Cnt_WEDPosnSnsr2ElecFlt_MFOP_Rx_NeNVMB_Cnt_WEDPosnSnsr2ElecFlt_MFOP, sw-syscond=1}
              IN_NeNVMB_Cnt_WEDPosnSnsr2PosnOOR_MFOP_Rx_NeNVMB_Cnt_WEDPosnSnsr2PosnOOR_MFOP: accessed-variable=NeNVMB_Cnt_WEDPosnSnsr2PosnOOR_MFOP_Rx.NeNVMB_Cnt_WEDPosnSnsr2PosnOOR_MFOP, variation-point={short-label=vpIN_NeNVMB_Cnt_WEDPosnSnsr2PosnOOR_MFOP_Rx_NeNVMB_Cnt_WEDPosnSnsr2PosnOOR_MFOP, sw-syscond=1}
        NVMB_PwrOff
          data-send-points:
            21 x access:
              OUT_NeNVMB_Cnt_WEDPosnSnsr1ElecFlt_MFOP_NeNVMB_Cnt_WEDPosnSnsr1ElecFlt_MFOP: accessed-variable=NeNVMB_Cnt_WEDPosnSnsr1ElecFlt_MFOP.NeNVMB_Cnt_WEDPosnSnsr1ElecFlt_MFOP, variation-point={short-label=vpOUT_NeNVMB_Cnt_WEDPosnSnsr1ElecFlt_MFOP_NeNVMB_Cnt_WEDPosnSnsr1ElecFlt_MFOP, sw-syscond=1}
              OUT_NeNVMB_Cnt_WEDPosnSnsr1PosnOOR_MFOP_NeNVMB_Cnt_WEDPosnSnsr1PosnOOR_MFOP: accessed-variable=NeNVMB_Cnt_WEDPosnSnsr1PosnOOR_MFOP.NeNVMB_Cnt_WEDPosnSnsr1PosnOOR_MFOP, variation-point={short-label=vpOUT_NeNVMB_Cnt_WEDPosnSnsr1PosnOOR_MFOP_NeNVMB_Cnt_WEDPosnSnsr1PosnOOR_MFOP, sw-syscond=1}
              OUT_NeNVMB_Cnt_WEDPosnSnsr2ElecFlt_MFOP_NeNVMB_Cnt_WEDPosnSnsr2ElecFlt_MFOP: accessed-variable=NeNVMB_Cnt_WEDPosnSnsr2ElecFlt_MFOP.NeNVMB_Cnt_WEDPosnSnsr2ElecFlt_MFOP, variation-point={short-label=vpOUT_NeNVMB_Cnt_WEDPosnSnsr2ElecFlt_MFOP_NeNVMB_Cnt_WEDPosnSnsr2ElecFlt_MFOP, sw-syscond=1}
              OUT_NeNVMB_Cnt_WEDPosnSnsr2PosnOOR_MFOP_NeNVMB_Cnt_WEDPosnSnsr2PosnOOR_MFOP: accessed-variable=NeNVMB_Cnt_WEDPosnSnsr2PosnOOR_MFOP.NeNVMB_Cnt_WEDPosnSnsr2PosnOOR_MFOP, variation-point={short-label=vpOUT_NeNVMB_Cnt_WEDPosnSnsr2PosnOOR_MFOP_NeNVMB_Cnt_WEDPosnSnsr2PosnOOR_MFOP, sw-syscond=1}
              OUT_NeNVMB_Cnt_LtWEDElecFlt_MFOP_NeNVMB_Cnt_LtWEDElecFlt_MFOP: accessed-variable=NeNVMB_Cnt_LtWEDElecFlt_MFOP.NeNVMB_Cnt_LtWEDElecFlt_MFOP, variation-point={short-label=vpOUT_NeNVMB_Cnt_LtWEDElecFlt_MFOP_NeNVMB_Cnt_LtWEDElecFlt_MFOP, sw-syscond=1}
              OUT_NeNVMB_Cnt_RtWEDElecFlt_MFOP_NeNVMB_Cnt_RtWEDElecFlt_MFOP: accessed-variable=NeNVMB_Cnt_RtWEDElecFlt_MFOP.NeNVMB_Cnt_RtWEDElecFlt_MFOP, variation-point={short-label=vpOUT_NeNVMB_Cnt_RtWEDElecFlt_MFOP_NeNVMB_Cnt_RtWEDElecFlt_MFOP, sw-syscond=1}
              OUT_NeNVMB_Cnt_FtRfgtShtOffVlvOC_MFOP_NeNVMB_Cnt_FtRfgtShtOffVlvOC_MFOP: accessed-variable=NeNVMB_Cnt_FtRfgtShtOffVlvOC_MFOP.NeNVMB_Cnt_FtRfgtShtOffVlvOC_MFOP, variation-point={short-label=vpOUT_NeNVMB_Cnt_FtRfgtShtOffVlvOC_MFOP_NeNVMB_Cnt_FtRfgtShtOffVlvOC_MFOP, sw-syscond=1}
              OUT_NeNVMB_Cnt_STGFtRfgtShtOffVlv_MFOP_NeNVMB_Cnt_STGFtRfgtShtOffVlv_MFOP: accessed-variable=NeNVMB_Cnt_STGFtRfgtShtOffVlv_MFOP.NeNVMB_Cnt_STGFtRfgtShtOffVlv_MFOP, variation-point={short-label=vpOUT_NeNVMB_Cnt_STGFtRfgtShtOffVlv_MFOP_NeNVMB_Cnt_STGFtRfgtShtOffVlv_MFOP, sw-syscond=1}
              OUT_NeNVMB_Cnt_STBFtRfgtShtOffVlv_MFOP_NeNVMB_Cnt_STBFtRfgtShtOffVlv_MFOP: accessed-variable=NeNVMB_Cnt_STBFtRfgtShtOffVlv_MFOP.NeNVMB_Cnt_STBFtRfgtShtOffVlv_MFOP, variation-point={short-label=vpOUT_NeNVMB_Cnt_STBFtRfgtShtOffVlv_MFOP_NeNVMB_Cnt_STBFtRfgtShtOffVlv_MFOP, sw-syscond=1}
              OUT_NeNVMB_Cnt_OCChillrShtOffVlv_MFOP_NeNVMB_Cnt_OCChillrShtOffVlv_MFOP: accessed-variable=NeNVMB_Cnt_OCChillrShtOffVlv_MFOP.NeNVMB_Cnt_OCChillrShtOffVlv_MFOP, variation-point={short-label=vpOUT_NeNVMB_Cnt_OCChillrShtOffVlv_MFOP_NeNVMB_Cnt_OCChillrShtOffVlv_MFOP, sw-syscond=1}
              OUT_NeNVMB_Cnt_STGChillrShtOffVlv_MFOP_NeNVMB_Cnt_STGChillrShtOffVlv_MFOP: accessed-variable=NeNVMB_Cnt_STGChillrShtOffVlv_MFOP.NeNVMB_Cnt_STGChillrShtOffVlv_MFOP, variation-point={short-label=vpOUT_NeNVMB_Cnt_STGChillrShtOffVlv_MFOP_NeNVMB_Cnt_STGChillrShtOffVlv_MFOP, sw-syscond=1}
              OUT_NeNVMB_Cnt_STBChillrShtOffVlv_MFOP_NeNVMB_Cnt_STBChillrShtOffVlv_MFOP: accessed-variable=NeNVMB_Cnt_STBChillrShtOffVlv_MFOP.NeNVMB_Cnt_STBChillrShtOffVlv_MFOP, variation-point={short-label=vpOUT_NeNVMB_Cnt_STBChillrShtOffVlv_MFOP_NeNVMB_Cnt_STBChillrShtOffVlv_MFOP, sw-syscond=1}
              OUT_NeNVMB_Cnt_HiTempShtOffVlvOC_MFOP_NeNVMB_Cnt_HiTempShtOffVlvOC_MFOP: accessed-variable=NeNVMB_Cnt_HiTempShtOffVlvOC_MFOP.NeNVMB_Cnt_HiTempShtOffVlvOC_MFOP, variation-point={short-label=vpOUT_NeNVMB_Cnt_HiTempShtOffVlvOC_MFOP_NeNVMB_Cnt_HiTempShtOffVlvOC_MFOP, sw-syscond=1}
              OUT_NeNVMB_Cnt_HiTempShtOffVlvSTG_MFOP_NeNVMB_Cnt_HiTempShtOffVlvSTG_MFOP: accessed-variable=NeNVMB_Cnt_HiTempShtOffVlvSTG_MFOP.NeNVMB_Cnt_HiTempShtOffVlvSTG_MFOP, variation-point={short-label=vpOUT_NeNVMB_Cnt_HiTempShtOffVlvSTG_MFOP_NeNVMB_Cnt_HiTempShtOffVlvSTG_MFOP, sw-syscond=1}
              OUT_NeNVMB_Cnt_HiTempShtOffVlvSTB_MFOP_NeNVMB_Cnt_HiTempShtOffVlvSTB_MFOP: accessed-variable=NeNVMB_Cnt_HiTempShtOffVlvSTB_MFOP.NeNVMB_Cnt_HiTempShtOffVlvSTB_MFOP, variation-point={short-label=vpOUT_NeNVMB_Cnt_HiTempShtOffVlvSTB_MFOP_NeNVMB_Cnt_HiTempShtOffVlvSTB_MFOP, sw-syscond=1}
              OUT_NeNVMB_Cnt_ThermSysEnbl_MFOP_NeNVMB_Cnt_ThermSysEnbl_MFOP: accessed-variable=NeNVMB_Cnt_ThermSysEnbl_MFOP.NeNVMB_Cnt_ThermSysEnbl_MFOP, variation-point={short-label=vpOUT_NeNVMB_Cnt_ThermSysEnbl_MFOP_NeNVMB_Cnt_ThermSysEnbl_MFOP, sw-syscond=1}
              OUT_NeNVMB_Cnt_RadrFanCtrlOC_MFOP_NeNVMB_Cnt_RadrFanCtrlOC_MFOP: accessed-variable=NeNVMB_Cnt_RadrFanCtrlOC_MFOP.NeNVMB_Cnt_RadrFanCtrlOC_MFOP, variation-point={short-label=vpOUT_NeNVMB_Cnt_RadrFanCtrlOC_MFOP_NeNVMB_Cnt_RadrFanCtrlOC_MFOP, sw-syscond=1}
              OUT_NeNVMB_Cnt_RadrFanCtrlSTG_MFOP_NeNVMB_Cnt_RadrFanCtrlSTG_MFOP: accessed-variable=NeNVMB_Cnt_RadrFanCtrlSTG_MFOP.NeNVMB_Cnt_RadrFanCtrlSTG_MFOP, variation-point={short-label=vpOUT_NeNVMB_Cnt_RadrFanCtrlSTG_MFOP_NeNVMB_Cnt_RadrFanCtrlSTG_MFOP, sw-syscond=1}
              OUT_NeNVMB_Cnt_RadrFanCtrlSTB_MFOP_NeNVMB_Cnt_RadrFanCtrlSTB_MFOP: accessed-variable=NeNVMB_Cnt_RadrFanCtrlSTB_MFOP.NeNVMB_Cnt_RadrFanCtrlSTB_MFOP, variation-point={short-label=vpOUT_NeNVMB_Cnt_RadrFanCtrlSTB_MFOP_NeNVMB_Cnt_RadrFanCtrlSTB_MFOP, sw-syscond=1}
              OUT_NeNVMB_Cnt_ACSwitchRelaySTG_MFOP_NeNVMB_Cnt_ACSwitchRelaySTG_MFOP: accessed-variable=NeNVMB_Cnt_ACSwitchRelaySTG_MFOP.NeNVMB_Cnt_ACSwitchRelaySTG_MFOP, variation-point={short-label=vpOUT_NeNVMB_Cnt_ACSwitchRelaySTG_MFOP_NeNVMB_Cnt_ACSwitchRelaySTG_MFOP, sw-syscond=1}
              OUT_NeNVMB_Cnt_ACSwitchRelaySTB_MFOP_NeNVMB_Cnt_ACSwitchRelaySTB_MFOP: accessed-variable=NeNVMB_Cnt_ACSwitchRelaySTB_MFOP.NeNVMB_Cnt_ACSwitchRelaySTB_MFOP, variation-point={short-label=vpOUT_NeNVMB_Cnt_ACSwitchRelaySTB_MFOP_NeNVMB_Cnt_ACSwitchRelaySTB_MFOP, sw-syscond=1}
        NVMB_MedTED1
          data-send-points:
            9 x access:
              OUT_VeNVMB_Cnt_FtRfgtShtOffVlvOC_MFOP_Value: accessed-variable=VeNVMB_Cnt_FtRfgtShtOffVlvOC_MFOP.Value, variation-point={short-label=vpOUT_VeNVMB_Cnt_FtRfgtShtOffVlvOC_MFOP_Value, sw-syscond=1}
              OUT_VeNVMB_Cnt_STGFtRfgtShtOffVlv_MFOP_Value: accessed-variable=VeNVMB_Cnt_STGFtRfgtShtOffVlv_MFOP.Value, variation-point={short-label=vpOUT_VeNVMB_Cnt_STGFtRfgtShtOffVlv_MFOP_Value, sw-syscond=1}
              OUT_VeNVMB_Cnt_STBFtRfgtShtOffVlv_MFOP_Value: accessed-variable=VeNVMB_Cnt_STBFtRfgtShtOffVlv_MFOP.Value, variation-point={short-label=vpOUT_VeNVMB_Cnt_STBFtRfgtShtOffVlv_MFOP_Value, sw-syscond=1}
              OUT_VeNVMB_Cnt_OCChillrShtOffVlv_MFOP_Value: accessed-variable=VeNVMB_Cnt_OCChillrShtOffVlv_MFOP.Value, variation-point={short-label=vpOUT_VeNVMB_Cnt_OCChillrShtOffVlv_MFOP_Value, sw-syscond=1}
              OUT_VeNVMB_Cnt_STGChillrShtOffVlv_MFOP_Value: accessed-variable=VeNVMB_Cnt_STGChillrShtOffVlv_MFOP.Value, variation-point={short-label=vpOUT_VeNVMB_Cnt_STGChillrShtOffVlv_MFOP_Value, sw-syscond=1}
              OUT_VeNVMB_Cnt_STBChillrShtOffVlv_MFOP_Value: accessed-variable=VeNVMB_Cnt_STBChillrShtOffVlv_MFOP.Value, variation-point={short-label=vpOUT_VeNVMB_Cnt_STBChillrShtOffVlv_MFOP_Value, sw-syscond=1}
              OUT_VeNVMB_Cnt_HiTempShtOffVlvOC_MFOP_Value: accessed-variable=VeNVMB_Cnt_HiTempShtOffVlvOC_MFOP.Value, variation-point={short-label=vpOUT_VeNVMB_Cnt_HiTempShtOffVlvOC_MFOP_Value, sw-syscond=1}
              OUT_VeNVMB_Cnt_HiTempShtOffVlvSTG_MFOP_Value: accessed-variable=VeNVMB_Cnt_HiTempShtOffVlvSTG_MFOP.Value, variation-point={short-label=vpOUT_VeNVMB_Cnt_HiTempShtOffVlvSTG_MFOP_Value, sw-syscond=1}
              OUT_VeNVMB_Cnt_HiTempShtOffVlvSTB_MFOP_Value: accessed-variable=VeNVMB_Cnt_HiTempShtOffVlvSTB_MFOP.Value, variation-point={short-label=vpOUT_VeNVMB_Cnt_HiTempShtOffVlvSTB_MFOP_Value, sw-syscond=1}
        NVMB_MedTEB1
          data-send-points:
            6 x access:
              OUT_VeNVMB_Cnt_WEDPosnSnsr1ElecFlt_MFOP_Value: accessed-variable=VeNVMB_Cnt_WEDPosnSnsr1ElecFlt_MFOP.Value, variation-point={short-label=vpOUT_VeNVMB_Cnt_WEDPosnSnsr1ElecFlt_MFOP_Value, sw-syscond=1}
              OUT_VeNVMB_Cnt_WEDPosnSnsr1PosnOOR_MFOP_Value: accessed-variable=VeNVMB_Cnt_WEDPosnSnsr1PosnOOR_MFOP.Value, variation-point={short-label=vpOUT_VeNVMB_Cnt_WEDPosnSnsr1PosnOOR_MFOP_Value, sw-syscond=1}
              OUT_VeNVMB_Cnt_WEDPosnSnsr2ElecFlt_MFOP_Value: accessed-variable=VeNVMB_Cnt_WEDPosnSnsr2ElecFlt_MFOP.Value, variation-point={short-label=vpOUT_VeNVMB_Cnt_WEDPosnSnsr2ElecFlt_MFOP_Value, sw-syscond=1}
              OUT_VeNVMB_Cnt_WEDPosnSnsr2PosnOOR_MFOP_Value: accessed-variable=VeNVMB_Cnt_WEDPosnSnsr2PosnOOR_MFOP.Value, variation-point={short-label=vpOUT_VeNVMB_Cnt_WEDPosnSnsr2PosnOOR_MFOP_Value, sw-syscond=1}
              OUT_VeNVMB_Cnt_LtWEDElecFlt_MFOP_Value: accessed-variable=VeNVMB_Cnt_LtWEDElecFlt_MFOP.Value, variation-point={short-label=vpOUT_VeNVMB_Cnt_LtWEDElecFlt_MFOP_Value, sw-syscond=1}
              OUT_VeNVMB_Cnt_RtWEDElecFlt_MFOP_Value: accessed-variable=VeNVMB_Cnt_RtWEDElecFlt_MFOP.Value, variation-point={short-label=vpOUT_VeNVMB_Cnt_RtWEDElecFlt_MFOP_Value, sw-syscond=1}
        NVMB_MedTEB2
          data-receive-point-by-arguments:
            6 x access:
              IN_VeADIB_Cnt_LtWEDElecFlt_MFOP_Value: accessed-variable=VeADIB_Cnt_LtWEDElecFlt_MFOP.Value, variation-point={short-label=vpIN_VeADIB_Cnt_LtWEDElecFlt_MFOP_Value, sw-syscond=1}
              IN_VeADIB_Cnt_RtWEDElecFlt_MFOP_Value: accessed-variable=VeADIB_Cnt_RtWEDElecFlt_MFOP.Value, variation-point={short-label=vpIN_VeADIB_Cnt_RtWEDElecFlt_MFOP_Value, sw-syscond=1}
              IN_VeADIB_Cnt_WEDPosnSnsr1ElecFlt_MFOP_Value: accessed-variable=VeADIB_Cnt_WEDPosnSnsr1ElecFlt_MFOP.Value, variation-point={short-label=vpIN_VeADIB_Cnt_WEDPosnSnsr1ElecFlt_MFOP_Value, sw-syscond=1}
              IN_VeADIB_Cnt_WEDPosnSnsr1PosnOOR_MFOP_Value: accessed-variable=VeADIB_Cnt_WEDPosnSnsr1PosnOOR_MFOP.Value, variation-point={short-label=vpIN_VeADIB_Cnt_WEDPosnSnsr1PosnOOR_MFOP_Value, sw-syscond=1}
              IN_VeADIB_Cnt_WEDPosnSnsr2ElecFlt_MFOP_Value: accessed-variable=VeADIB_Cnt_WEDPosnSnsr2ElecFlt_MFOP.Value, variation-point={short-label=vpIN_VeADIB_Cnt_WEDPosnSnsr2ElecFlt_MFOP_Value, sw-syscond=1}
              IN_VeADIB_Cnt_WEDPosnSnsr2PosnOOR_MFOP_Value: accessed-variable=VeADIB_Cnt_WEDPosnSnsr2PosnOOR_MFOP.Value, variation-point={short-label=vpIN_VeADIB_Cnt_WEDPosnSnsr2PosnOOR_MFOP_Value, sw-syscond=1}
        NVMB_MedTED2
          data-receive-point-by-arguments:
            9 x access:
              IN_VeCOUB_Cnt_FtRfgtShtOffVlvOC_MFOP_Value: accessed-variable=VeCOUB_Cnt_FtRfgtShtOffVlvOC_MFOP.Value, variation-point={short-label=vpIN_VeCOUB_Cnt_FtRfgtShtOffVlvOC_MFOP_Value, sw-syscond=1}
              IN_VeCOUB_Cnt_HiTempShtOffVlvOC_MFOP_Value: accessed-variable=VeCOUB_Cnt_HiTempShtOffVlvOC_MFOP.Value, variation-point={short-label=vpIN_VeCOUB_Cnt_HiTempShtOffVlvOC_MFOP_Value, sw-syscond=1}
              IN_VeCOUB_Cnt_HiTempShtOffVlvSTB_MFOP_Value: accessed-variable=VeCOUB_Cnt_HiTempShtOffVlvSTB_MFOP.Value, variation-point={short-label=vpIN_VeCOUB_Cnt_HiTempShtOffVlvSTB_MFOP_Value, sw-syscond=1}
              IN_VeCOUB_Cnt_HiTempShtOffVlvSTG_MFOP_Value: accessed-variable=VeCOUB_Cnt_HiTempShtOffVlvSTG_MFOP.Value, variation-point={short-label=vpIN_VeCOUB_Cnt_HiTempShtOffVlvSTG_MFOP_Value, sw-syscond=1}
              IN_VeCOUB_Cnt_OCChillrShtOffVlv_MFOP_Value: accessed-variable=VeCOUB_Cnt_OCChillrShtOffVlv_MFOP.Value, variation-point={short-label=vpIN_VeCOUB_Cnt_OCChillrShtOffVlv_MFOP_Value, sw-syscond=1}
              IN_VeCOUB_Cnt_STBChillrShtOffVlv_MFOP_Value: accessed-variable=VeCOUB_Cnt_STBChillrShtOffVlv_MFOP.Value, variation-point={short-label=vpIN_VeCOUB_Cnt_STBChillrShtOffVlv_MFOP_Value, sw-syscond=1}
              IN_VeCOUB_Cnt_STBFtRfgtShtOffVlv_MFOP_Value: accessed-variable=VeCOUB_Cnt_STBFtRfgtShtOffVlv_MFOP.Value, variation-point={short-label=vpIN_VeCOUB_Cnt_STBFtRfgtShtOffVlv_MFOP_Value, sw-syscond=1}
              IN_VeCOUB_Cnt_STGChillrShtOffVlv_MFOP_Value: accessed-variable=VeCOUB_Cnt_STGChillrShtOffVlv_MFOP.Value, variation-point={short-label=vpIN_VeCOUB_Cnt_STGChillrShtOffVlv_MFOP_Value, sw-syscond=1}
              IN_VeCOUB_Cnt_STGFtRfgtShtOffVlv_MFOP_Value: accessed-variable=VeCOUB_Cnt_STGFtRfgtShtOffVlv_MFOP.Value, variation-point={short-label=vpIN_VeCOUB_Cnt_STGFtRfgtShtOffVlv_MFOP_Value, sw-syscond=1}
        NVMB_MedTEH1
          data-send-points:
            6 x access:
              OUT_VeNVMB_Cnt_ThermSysEnbl_MFOP_Value: accessed-variable=VeNVMB_Cnt_ThermSysEnbl_MFOP.Value, variation-point={short-label=vpOUT_VeNVMB_Cnt_ThermSysEnbl_MFOP_Value, sw-syscond=1}
              OUT_VeNVMB_Cnt_RadrFanCtrlOC_MFOP_Value: accessed-variable=VeNVMB_Cnt_RadrFanCtrlOC_MFOP.Value, variation-point={short-label=vpOUT_VeNVMB_Cnt_RadrFanCtrlOC_MFOP_Value, sw-syscond=1}
              OUT_VeNVMB_Cnt_RadrFanCtrlSTG_MFOP_Value: accessed-variable=VeNVMB_Cnt_RadrFanCtrlSTG_MFOP.Value, variation-point={short-label=vpOUT_VeNVMB_Cnt_RadrFanCtrlSTG_MFOP_Value, sw-syscond=1}
              OUT_VeNVMB_Cnt_RadrFanCtrlSTB_MFOP_Value: accessed-variable=VeNVMB_Cnt_RadrFanCtrlSTB_MFOP.Value, variation-point={short-label=vpOUT_VeNVMB_Cnt_RadrFanCtrlSTB_MFOP_Value, sw-syscond=1}
              OUT_VeNVMB_Cnt_ACSwitchRelaySTG_MFOP_Value: accessed-variable=VeNVMB_Cnt_ACSwitchRelaySTG_MFOP.Value, variation-point={short-label=vpOUT_VeNVMB_Cnt_ACSwitchRelaySTG_MFOP_Value, sw-syscond=1}
              OUT_VeNVMB_Cnt_ACSwitchRelaySTB_MFOP_Value: accessed-variable=VeNVMB_Cnt_ACSwitchRelaySTB_MFOP.Value, variation-point={short-label=vpOUT_VeNVMB_Cnt_ACSwitchRelaySTB_MFOP_Value, sw-syscond=1}
        NVMB_MedTEH2
          data-receive-point-by-arguments:
            6 x access:
              IN_VeCOUB_Cnt_ACSwitchRelaySTB_MFOP_Value: accessed-variable=VeCOUB_Cnt_ACSwitchRelaySTB_MFOP.Value, variation-point={short-label=vpIN_VeCOUB_Cnt_ACSwitchRelaySTB_MFOP_Value, sw-syscond=1}
              IN_VeCOUB_Cnt_ACSwitchRelaySTG_MFOP_Value: accessed-variable=VeCOUB_Cnt_ACSwitchRelaySTG_MFOP.Value, variation-point={short-label=vpIN_VeCOUB_Cnt_ACSwitchRelaySTG_MFOP_Value, sw-syscond=1}
              IN_VeCOUB_Cnt_RadrFanCtrlOC_MFOP_Value: accessed-variable=VeCOUB_Cnt_RadrFanCtrlOC_MFOP.Value, variation-point={short-label=vpIN_VeCOUB_Cnt_RadrFanCtrlOC_MFOP_Value, sw-syscond=1}
              IN_VeCOUB_Cnt_RadrFanCtrlSTB_MFOP_Value: accessed-variable=VeCOUB_Cnt_RadrFanCtrlSTB_MFOP.Value, variation-point={short-label=vpIN_VeCOUB_Cnt_RadrFanCtrlSTB_MFOP_Value, sw-syscond=1}
              IN_VeCOUB_Cnt_RadrFanCtrlSTG_MFOP_Value: accessed-variable=VeCOUB_Cnt_RadrFanCtrlSTG_MFOP.Value, variation-point={short-label=vpIN_VeCOUB_Cnt_RadrFanCtrlSTG_MFOP_Value, sw-syscond=1}
              IN_VeCOUB_Cnt_ThermSysEnbl_MFOP_Value: accessed-variable=VeCOUB_Cnt_ThermSysEnbl_MFOP.Value, variation-point={short-label=vpIN_VeCOUB_Cnt_ThermSysEnbl_MFOP_Value, sw-syscond=1}
      9 x variation point proxy, all with category=CONDITION:
        Variant_NVMB_ACPWRSWRLY_Presence: condition-access=1
        Variant_NVMB_CSOV_Presence: condition-access=1
        Variant_NVMB_EPTWUP_Presence: condition-access=0
        Variant_NVMB_FRSOV_Presence: condition-access=1
        Variant_NVMB_HTSOV_Presence: condition-access=1
        Variant_NVMB_OILPUMP_Presence: condition-access=0
        Variant_NVMB_RADFAN_Presence: condition-access=1
        Variant_NVMB_THRMLSYSEN_Presence: condition-access=1
        Variant_NVMB_WED_Presence: condition-access=1
